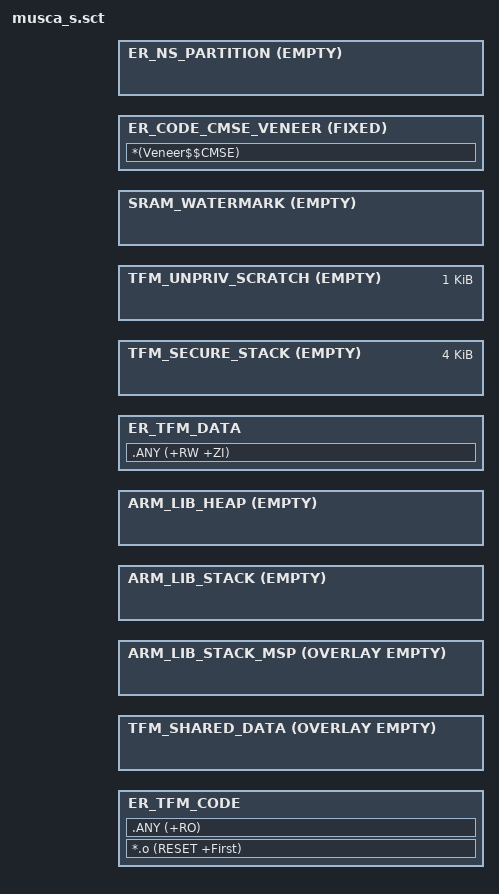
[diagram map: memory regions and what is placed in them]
#! armclang --target=arm-arm-none-eabi -march=armv8-m.main -E -xc

/*
 * Copyright (c) 2018-2020 Arm Limited
 *
 * SPDX-License-Identifier: Apache-2.0
 *
 * Licensed under the Apache License, Version 2.0 (the "License");
 * you may not use this file except in compliance with the License.
 * You may obtain a copy of the License at
 *
 *     http://www.apache.org/licenses/LICENSE-2.0
 *
 * Unless required by applicable law or agreed to in writing, software
 * distributed under the License is distributed on an "AS IS" BASIS,
 * WITHOUT WARRANTIES OR CONDITIONS OF ANY KIND, either express or implied.
 * See the License for the specific language governing permissions and
 * limitations under the License.
 */

#include "../../../partition/region_defs.h"

#if !defined(TFM_LVL)
  #define TFM_LVL   1
#endif

#if !defined(MBED_ROM_START)
  #define MBED_ROM_START    S_CODE_START      // 0x1A020400
#endif

#if !defined(MBED_ROM_SIZE)
  #define MBED_ROM_SIZE     IMAGE_S_CODE_SIZE // 0x4f800
#endif

#if !defined(MBED_RAM_START)
  #define MBED_RAM_START    S_DATA_START      // 0x30000000
#endif

#if !defined(MBED_RAM_SIZE)
  #define MBED_RAM_SIZE     S_DATA_SIZE       // 0x40000
#endif

LR_CODE MBED_ROM_START MBED_ROM_SIZE {

    /****  This initial section contains common code for TEE */
    ER_TFM_CODE MBED_ROM_START S_CODE_SIZE {
        *.o (RESET +First)
        .ANY (+RO)
    }

#if TFM_LVL == 1

    /* Shared area between BL2 and runtime to exchange data */
    TFM_SHARED_DATA MBED_RAM_START ALIGN 32 OVERLAY EMPTY BOOT_TFM_SHARED_DATA_SIZE {
    }

    /* MSP */
    ARM_LIB_STACK_MSP MBED_RAM_START ALIGN 32 OVERLAY EMPTY S_MSP_STACK_SIZE {
    }

    /* PSP */
    ARM_LIB_STACK +0 ALIGN 32 EMPTY S_PSP_STACK_SIZE {
    }

    ARM_LIB_HEAP +0 ALIGN 8 EMPTY S_HEAP_SIZE {
    }

    ER_TFM_DATA +0 {
        .ANY (+RW +ZI)
    }

    TFM_SECURE_STACK +0 ALIGN 128 EMPTY 0x1000 {
    }

    TFM_UNPRIV_SCRATCH +0 ALIGN 32 EMPTY 0x400 {
    }

#else /* TFM_LVL == 1 */

    /**** Unprivileged Secure code start here */
    TFM_UNPRIV_CODE +0 ALIGN 32 {
        tfm_spm_services.o (+RO)
        device_definition.o (+RO)
        *(SFN)
        *armlib*
    }

    TFM_SP_PLATFORM +0 ALIGN 32 {
        *tfm_platform* (+RO)
        *(TFM_SP_PLATFORM_ATTR_FN)
    }

    /* Shared area between BL2 and runtime to exchange data */
    TFM_SHARED_DATA MBED_RAM_START ALIGN 32 OVERLAY EMPTY BOOT_TFM_SHARED_DATA_SIZE {
    }

    /* MSP */
    ARM_LIB_STACK_MSP MBED_RAM_START ALIGN 32 OVERLAY EMPTY S_MSP_STACK_SIZE {
    }

    /* PSP */
    ARM_LIB_STACK +0 ALIGN 32 EMPTY S_PSP_STACK_SIZE {
    }

    ARM_LIB_HEAP +0 ALIGN 8 EMPTY S_HEAP_SIZE {
    }

    ER_TFM_DATA +0 {
        .ANY (+RW +ZI)
    }

    TFM_UNPRIV_RO_DATA +0 ALIGN 32 {
        tfm_spm_services.o (+RW +ZI)
        device_definition.o (+RW +ZI)
    }

    TFM_UNPRIV_SCRATCH +0 ALIGN 32 EMPTY 0x400 {
    }

    TFM_SP_PLATFORM_DATA +0 ALIGN 32 {
        *tfm_platform* (+RW +ZI)
    }

    TFM_SP_PLATFORM_STACK +0 ALIGN 128 EMPTY 0x0400 {
    }

#endif /* TFM_LVL == 1 */

    /* This empty, zero long execution region is here to mark the limit address
     * of the last execution region that is allocated in SRAM.
     */
    SRAM_WATERMARK +0 EMPTY 0x0 {
    }

    ER_CODE_CMSE_VENEER CMSE_VENEER_REGION_START FIXED PADVALUE 0xFFFFFFFF CMSE_VENEER_REGION_SIZE {
        *(Veneer$$CMSE)
    }

    /* Make sure that the sections allocated in the SRAM does not exceed the
     * size of the SRAM available.
     */
    ScatterAssert(ImageLimit(SRAM_WATERMARK) <= MBED_RAM_START + MBED_RAM_SIZE)
}


LR_NS_PARTITION NS_PARTITION_START {
    /* Reserved place for NS application.
     * No code will be placed here, just address of this region is used in the
     * secure code to configure certain HW components.
     */
    ER_NS_PARTITION NS_PARTITION_START EMPTY NS_PARTITION_SIZE {
    }
}
